# S32M24x register map
Vendor: NXP Semiconductors; File version: 1.5
CPU: CM4 r0p1, little endian, MPU, FPU, VTOR, 4 interrupt priority bits
Registers are 32-bit, read-write, reset 0x0 unless marked. A register's access mark holds for its fields unless they carry their own. Offsets are from the block's base; [hi:lo] are bit positions; 'fields as' and 'values as' point back to an identical list.

## PMC_AE — PMC
Base 0x00000100
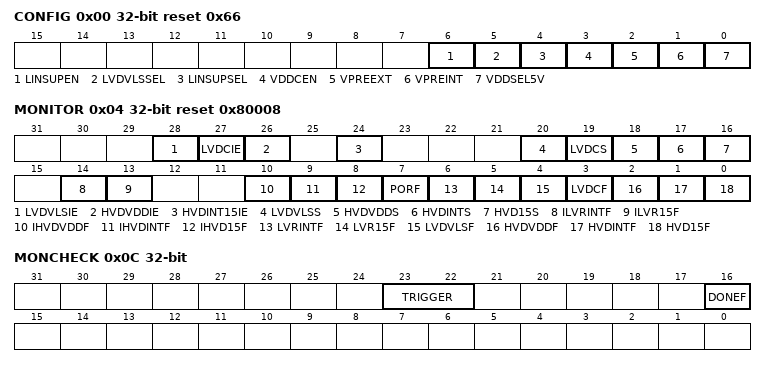
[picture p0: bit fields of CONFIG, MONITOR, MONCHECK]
0x00 CONFIG reset 0x66 — PMC Configuration Register
  [6] LINSUPEN — LINPHY supply enable
    0=DISABLE (LINPHY supply is high ohmic (off)); 1=ENABLE (LINPHY supply is as selected by LINSUPSEL bit)
  [5] LVDVLSSEL — LVD VLS select
    0=SEL5V5 (LVD threshold on VLS supply is 5.5V); 1=SEL6V5 (LVD threshold on VLS supply is 6.5V)
  [4] LINSUPSEL — LINPHY supply select
    0=SELVSUP (LINPHY supply connects to VSUP pin); 1=SELHD (LINPHY supply connects to HD pin (of GDU))
  [3] VDDCEN — VDDC enable
    0=DISABLE (VDDC is disabled); 1=ENABLE (VDDC is enabled and regulated to 5V)
  [2] VPREEXT — VPRE external regulator enable
    0=DISABLE (PMC controlled (GCTL pin) external VPRE regulator is off); 1=ENABLE (PMC controlled (GCTL pin) external VPRE regulator is on)
  [1] VPREINT — VPRE internal regulator enable
    0=DISABLE (PMC internal VPRE regulator is off); 1=ENABLE (PMC internal VPRE regulator is on)
  [0] VDDSEL5V — VDD voltage level select
    0=SELECT3V3 (VDD is regulated to 3.3V); 1=SELECT5V (VDD is regulated to 5V)
0x04 MONITOR reset 0x80008 (reset mask 0xFFFF9818) — PMC Monitor Register
  [28] LVDVLSIE — LVD on VLS interrupt enable
    0=DISABLE (Low voltage detect interrupts on VLS disabled); 1=ENABLE (Low voltage detect interrupts on VLS enabled)
  [27] LVDCIE — LVD on VDDC interrupt enable.
    0=DISABLE (Low voltage detect interrupts on VDDC disabled); 1=ENABLE (Low voltage detect interrupts on VDDC enabled)
  [26] HVDVDDIE — HVD on VDD interrupt enable
    0=DISABLE (High voltage detect interrupt disabled); 1=ENABLE (High voltage detect interrupt enabled)
  [24] HVDINT15IE — HVD on VDDINT or VDD15 interrupt enable
    values as HVDVDDIE
  [20] LVDVLSS ro — LVDVLS status
    0=VOLTAGE_GOOD (Voltage on VLS is above low-voltage detect threshold and VLS supply is enabled (GDUEN=1)); 1=VOLTAGE_TOO_LOW (Voltage on VLS is below low-voltage detect threshold or VLS supply is disabled (GDUEN=0))
  [19] LVDCS ro — LVDC status
    0=VOLTAGE_GOOD (Voltage on VDDC is above low-voltage detect threshold and VDDC supply is enabled (VDDCEN=1)); 1=VOLTAGE_TOO_LOW (Voltage on VDDC is below low-voltage detect threshold or VDDC supply is disabled (VDDCEN=0))
  [18] HVDVDDS ro — HVDVDD status
    0=VOLTAGE_GOOD (Voltage on VDD is below high-voltage detect threshold); 1=VOLTAGE_TOO_HIGH (Voltage on VDD is above high-voltage detect threshold)
  [17] HVDINTS ro — HVDINT status
    0=VOLTAGE_GOOD (Voltage on VDDINT is below high-voltage detect threshold); 1=VOLTAGE_TOO_HIGH (Voltage on VDDINT is above high-voltage detect threshold)
  [16] HVD15S ro — HVD15 status
    0=VOLTAGE_GOOD (Voltage on VDD15 is below high-voltage detect threshold); 1=VOLTAGE_TOO_HIGH (Voltage on VDD15 is above high-voltage detect threshold)
  [14] ILVRINTF — Inverse LVRINT flag
    0=EVENT (Low-voltage reset event has occurred); 1=NO_EVENT (No low-voltage reset event has occurred)
  [13] ILVR15F — Inverse LVR15 flag
    values as ILVRINTF
  [10] IHVDVDDF — Inverse HVDVDD flag
    0=EVENT (High-voltage event has occurred); 1=NO_EVENT (No high-voltage event has occurred)
  [9] IHVDINTF — Inverse HVDINT flag
    values as IHVDVDDF
  [8] IHVD15F — Inverse HVD15 flag
    values as IHVDVDDF
  [7] PORF write-1-clears — POR flag
    0=NO_EVENT (No power-on reset event has occurred); 1=EVENT (Power-on reset event has occurred)
  [6] LVRINTF write-1-clears — LVRINT flag
    0=NO_EVENT (No low-voltage reset event has occurred); 1=EVENT (Low-voltage reset event has occurred)
  [5] LVR15F write-1-clears — LVR15 flag
    values as LVRINTF
  [4] LVDVLSF write-1-clears — LVDVLS flag
    0=NO_EVENT (No low voltage event detected on VLS supply or VLS supply is disabled (GDUEN=0)); 1=EVENT (Low voltage event detected on VLS supply and VLS supply is enabled (GDUEN=1))
  [3] LVDCF write-1-clears — LVDC flag
    0=NO_EVENT (No change on LVDCS); 1=EVENT (LVDCS has changed)
  [2] HVDVDDF write-1-clears — HVDVDD flag
    0=NO_EVENT (No high voltage event detected on VDD supply); 1=EVENT (High voltage event detected on VDD supply)
  [1] HVDINTF write-1-clears — HVDINT flag
    0=NO_EVENT (No high voltage event detected on VDDINT supply); 1=EVENT (High voltage event detected on VDDINT supply)
  [0] HVD15F write-1-clears — HVD15 flag
    0=NO_EVENT (No high voltage event detected on VDD15 supply); 1=EVENT (High voltage event detected on VDD15 supply)
0x0C MONCHECK (reset mask 0xFF3EFFFF) — Monitor Self Check Register
  [23:22] TRIGGER — Monitor Self Check Trigger Bits
    1=DISABLE (Changing the value from 10 to 01 will trigger a monitor self check. A system reset will be the consequence.); 2=ENABLE (Default after power-up. Self check idle and disabled)
  [16] DONEF write-1-clears — Self Test Done Flag
    0=NOEVENT (No self check even has occurred); 1=EVENT (Self check has been executed)

## Notices in the file
Copyright 2016-2024 NXP
NXP Confidential and Proprietary. This software is owned or controlled
by NXP and may only be used strictly in accordance with the applicable
license terms. By expressly accepting such terms or by downloading,
installing, activating and/or otherwise using the software, you are
agreeing that you have read, and that you agree to comply with and are
bound by, such license terms. If you do not agree to be bound by the
applicable license terms, then you may not retain, install, activate
or otherwise use the software.
